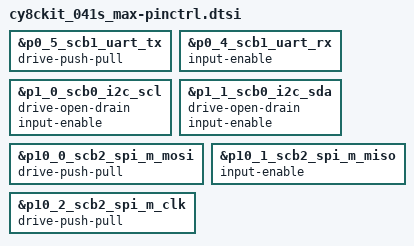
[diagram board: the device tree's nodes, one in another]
/*
 * SPDX-FileCopyrightText: Copyright (c) 2026 Infineon Technologies AG,
 * SPDX-FileCopyrightText: or an affiliate of Infineon Technologies AG. All rights reserved.
 *
 * SPDX-License-Identifier: Apache-2.0
 */

/* Configure pin drive mode for uart pins */
&p0_5_scb1_uart_tx {
	drive-push-pull;
};

&p0_4_scb1_uart_rx {
	input-enable;
};

/* Configure pin drive mode for i2c pins */
&p1_0_scb0_i2c_scl {
	drive-open-drain;
	input-enable;
};

&p1_1_scb0_i2c_sda {
	drive-open-drain;
	input-enable;
};

/* Configure pin drive mode for the Arduino SPI pins */
&p10_0_scb2_spi_m_mosi {
	drive-push-pull;
};

&p10_1_scb2_spi_m_miso {
	input-enable;
};

&p10_2_scb2_spi_m_clk {
	drive-push-pull;
};
